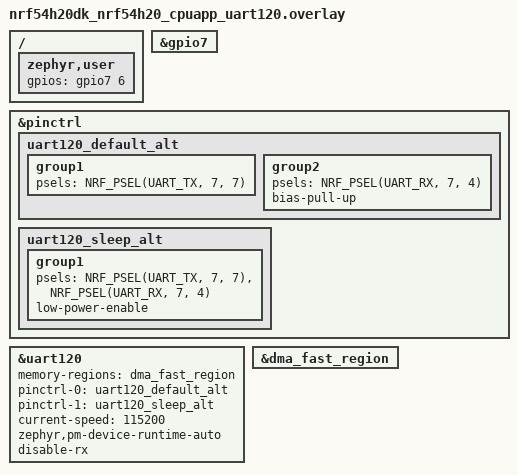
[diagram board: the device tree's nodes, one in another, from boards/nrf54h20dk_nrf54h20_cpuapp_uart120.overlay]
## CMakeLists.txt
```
#
# Copyright (c) 2025 Nordic Semiconductor ASA
#
# SPDX-License-Identifier: LicenseRef-Nordic-5-Clause
#

cmake_minimum_required(VERSION 3.20.0)
find_package(Zephyr REQUIRED HINTS $ENV{ZEPHYR_BASE})
project(uart_baudrate_test)

FILE(GLOB app_sources src/*.c)
target_sources(app PRIVATE ${app_sources})
```

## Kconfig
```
#
# Copyright (c) 2025 Nordic Semiconductor ASA
#
# SPDX-License-Identifier: LicenseRef-Nordic-5-Clause
#

source "Kconfig.zephyr"

config ALLOWED_DEVIATION
	int "Allowed deviation (%) for UART timing checks"
	default 25
	range 0 100
	help
	  Maximum allowed deviation (%) from the programmed values for the test to be
	  considered a PASS. For example, if set to 5, the measured period of bit
	  can deviate by up to 5% from the programmed values for the test to pass.
```

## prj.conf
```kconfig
CONFIG_SERIAL=y
CONFIG_ZTEST=y
CONFIG_UART_USE_RUNTIME_CONFIGURE=y
CONFIG_CBPRINTF_FP_SUPPORT=y
CONFIG_SPEED_OPTIMIZATIONS=y
CONFIG_UART_ASYNC_API=y
```

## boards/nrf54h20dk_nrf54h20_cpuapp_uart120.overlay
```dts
/*
 * Test requires wire connection between:
 *  - uart120 TX at P7.07 <-> GPIO input at P7.06
 */

/ {
	zephyr,user {
		gpios = <&gpio7 6 GPIO_ACTIVE_HIGH>;
	};
};

&gpio7 {
	status = "okay";
};

&pinctrl {
	uart120_default_alt: uart120_default_alt {
		group1 {
			psels = <NRF_PSEL(UART_TX, 7, 7)>;
		};
		group2 {
			psels = <NRF_PSEL(UART_RX, 7, 4)>;
			bias-pull-up;
		};
	};

	uart120_sleep_alt: uart120_sleep_alt {
		group1 {
			psels = <NRF_PSEL(UART_TX, 7, 7)>,
				<NRF_PSEL(UART_RX, 7, 4)>;
			low-power-enable;
		};
	};
};

dut: &uart120 {
	status = "okay";
	memory-regions = <&dma_fast_region>;
	pinctrl-0 = <&uart120_default_alt>;
	pinctrl-1 = <&uart120_sleep_alt>;
	pinctrl-names = "default", "sleep";
	current-speed = <115200>;
	zephyr,pm-device-runtime-auto;
	disable-rx;
};

&dma_fast_region {
	status = "okay";
};
```

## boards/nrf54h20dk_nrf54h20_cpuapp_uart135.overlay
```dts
/*
 * Test requires wire connection between:
 *  - uart135 TX at P0.06 <-> GPIO input at P0.07
 */

/ {
	zephyr,user {
		gpios = <&gpio0 7 GPIO_ACTIVE_HIGH>;
	};
};

&gpio0 {
	status = "okay";
};

&pinctrl {
	uart135_default_alt: uart135_default_alt {
		group1 {
			psels = <NRF_PSEL(UART_RX, 0, 9)>;
				bias-pull-up;
		};
		group2 {
			psels = <NRF_PSEL(UART_TX, 0, 6)>;
		};
	};

	uart135_sleep_alt: uart135_sleep_alt {
		group1 {
			psels = <NRF_PSEL(UART_TX, 0, 6)>,
				<NRF_PSEL(UART_RX, 0, 9)>;
			low-power-enable;
		};
	};
};

dut: &uart135 {
	status = "okay";
	memory-regions = <&cpuapp_dma_region>;
	pinctrl-0 = <&uart135_default_alt>;
	pinctrl-1 = <&uart135_sleep_alt>;
	pinctrl-names = "default", "sleep";
	current-speed = <115200>;
	disable-rx;
};
```

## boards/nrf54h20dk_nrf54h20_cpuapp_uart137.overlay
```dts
/*
 * Test requires wire connection between:
 *  - uart137 TX at P0.08 <-> GPIO input at P0.09
 */

/ {
	zephyr,user {
		gpios = <&gpio0 9 GPIO_ACTIVE_HIGH>;
	};
};

&gpio0 {
	status = "okay";
};

&pinctrl {
	uart137_default_alt: uart137_default_alt {
		group1 {
			psels = <NRF_PSEL(UART_RX, 0, 7)>;
			bias-pull-up;
		};
		group2 {
			psels = <NRF_PSEL(UART_TX, 0, 8)>;
		};
	};

	uart137_sleep_alt: uart137_sleep_alt {
		group1 {
			psels = <NRF_PSEL(UART_TX, 0, 8)>,
				<NRF_PSEL(UART_RX, 0, 9)>;
			low-power-enable;
		};
	};
};

dut: &uart137 {
	status = "okay";
	memory-regions = <&cpuapp_dma_region>;
	pinctrl-0 = <&uart137_default_alt>;
	pinctrl-1 = <&uart137_sleep_alt>;
	pinctrl-names = "default", "sleep";
	current-speed = <115200>;
	disable-rx;
};
```

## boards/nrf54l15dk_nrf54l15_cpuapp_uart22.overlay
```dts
/*
 * Test requires wire connection between:
 *  - uart21 TX at P1.9 <-> GPIO input at P1.8
 */


/ {
	zephyr,user {
		gpios = <&gpio1 8 GPIO_ACTIVE_HIGH>;
	};
};

&gpio1 {
	status = "okay";
};

&pinctrl {
	uart22_default: uart22_default {
		group1 {
			psels = <NRF_PSEL(UART_TX, 1, 9)>,
				<NRF_PSEL(UART_RX, 1, 11)>;
				bias-pull-up;
		};
	};

	uart22_sleep: uart22_sleep {
		group1 {
			psels = <NRF_PSEL(UART_TX, 1, 9)>,
				<NRF_PSEL(UART_RX, 1, 11)>;
			low-power-enable;
		};
	};
};

dut: &uart22 {
	status = "okay";
	current-speed = <115200>;
	pinctrl-0 = <&uart22_default>;
	pinctrl-1 = <&uart22_sleep>;
	pinctrl-names = "default", "sleep";
	disable-rx;
};
```

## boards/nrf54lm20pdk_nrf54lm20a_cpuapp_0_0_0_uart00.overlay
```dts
/*
 * Test requires wire connection between:
 *  - uart00 TX at P2.08 <-> GPIO input at P2.09
 */

/ {
	zephyr,user {
		gpios = <&gpio2 9 GPIO_ACTIVE_HIGH>;
	};
};

&gpio2 {
	status = "okay";
};

&pinctrl {
	uart00_default: uart00_default {
		group1 {
			psels = <NRF_PSEL(UART_TX, 2, 8)>,
				<NRF_PSEL(UART_RX, 2, 7)>;
				bias-pull-up;
		};
	};

	uart00_sleep: uart00_sleep {
		group1 {
			psels = <NRF_PSEL(UART_TX, 2, 8)>,
				<NRF_PSEL(UART_RX, 2, 7)>;
			low-power-enable;
		};
	};
};

dut: &uart00 {
	status = "okay";
	current-speed = <115200>;
	pinctrl-0 = <&uart00_default>;
	pinctrl-1 = <&uart00_sleep>;
	pinctrl-names = "default", "sleep";
	disable-rx;
};
```

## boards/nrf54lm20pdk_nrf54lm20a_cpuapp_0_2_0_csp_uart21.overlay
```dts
/*
 * Test requires wire connection between:
 *  - uart21 TX at P1.13 <-> GPIO input at P1.14
 */

/ {
	zephyr,user {
		gpios = <&gpio1 14 GPIO_ACTIVE_HIGH>;
	};
};

&gpio1 {
	status = "okay";
};

&pinctrl {
	uart21_default: uart21_default {
		group1 {
			psels = <NRF_PSEL(UART_TX, 1, 13)>,
				<NRF_PSEL(UART_RX, 1, 23)>;
				bias-pull-up;
		};
	};

	uart21_sleep: uart21_sleep {
		group1 {
			psels = <NRF_PSEL(UART_TX, 1, 13)>,
				<NRF_PSEL(UART_RX, 1, 23)>;
			low-power-enable;
		};
	};
};

dut: &uart21 {
	status = "okay";
	current-speed = <115200>;
	pinctrl-0 = <&uart21_default>;
	pinctrl-1 = <&uart21_sleep>;
	pinctrl-names = "default", "sleep";
	disable-rx;
};
```

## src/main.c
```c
/*
 * Copyright (c) 2025 Nordic Semiconductor ASA
 *
 * SPDX-License-Identifier: LicenseRef-Nordic-5-Clause
 */

#include <zephyr/device.h>
#include <zephyr/devicetree.h>
#include <zephyr/drivers/uart.h>
#include <zephyr/kernel.h>
#include <zephyr/ztest.h>
#include <zephyr/drivers/gpio.h>
#include <stdlib.h>
#include <math.h>

static const struct gpio_dt_spec gpio_spec =
	GPIO_DT_SPEC_GET_BY_IDX(DT_PATH(zephyr_user), gpios, 0);
static const struct device *const uart_dev = DEVICE_DT_GET(DT_NODELABEL(dut));

static const uint8_t tx_buf[1] = {0x00};

#define PIN_STATE_SIZE 16384
static int pin_state[PIN_STATE_SIZE] = {};

#define REPEAT_NUMBER 10

#ifdef CONFIG_UART_INTERRUPT_DRIVEN
static void uart_fifo_callback(const struct device *dev, void *user_data)
{
	int ret;

	ARG_UNUSED(user_data);

	ret = uart_irq_update(dev);
	zassert_true(ret >= 0, "uart_irq_update: %d\n", ret);

	ret = uart_irq_tx_ready(dev);
	zassert_true(ret >= 0, "uart_irq_tx_ready: %d\n", ret);

	ret = uart_fifo_fill(dev, (uint8_t *)&tx_buf, sizeof(tx_buf));
	zassert_true(ret == sizeof(tx_buf), "uart_fifo_fill: %d\n", ret);
	uart_irq_tx_disable(dev);
}
#endif

static void check_timing(const struct gpio_dt_spec *gpio_dt, uint32_t baudrate)
{
	uint64_t cycles_s_sys;
	struct uart_config test_uart_config;
	int ret;
	uint32_t cycle_start_time;
	uint32_t cycle_stop_time;
	double gpio_read_time_us_mean;
	int32_t start_index;
	int32_t stop_index;
	int32_t start_index_count_zero;
	double bit_diviation_mean;
	double symbol_diviation_mean;

	ret = uart_config_get(uart_dev, &test_uart_config);
	zassert_equal(ret, 0, "uart_config_get: %d\n", ret);

	test_uart_config.parity = UART_CFG_PARITY_EVEN;
	test_uart_config.stop_bits = UART_CFG_STOP_BITS_2;
	test_uart_config.flow_ctrl = UART_CFG_FLOW_CTRL_NONE;
	test_uart_config.baudrate = baudrate;
	ret = uart_configure(uart_dev, &test_uart_config);
	if (ret == -ENOTSUP) {
		TC_PRINT("[%d] Not supported\n", baudrate);
		ztest_test_skip();
	}
	zassert_equal(ret, 0, "uart_configure: %d\n", ret);

	cycles_s_sys = (uint64_t)sys_clock_hw_cycles_per_sec();
	TC_PRINT("Cycles: %llu cycles\n", cycles_s_sys);

	/*
	 * Measure time needed to read gpios
	 */
	gpio_read_time_us_mean = 0;
	for (uint32_t t = 0; t < REPEAT_NUMBER; ++t) {
		cycle_start_time = k_cycle_get_32();
		for (uint32_t i = 0; i < PIN_STATE_SIZE; ++i) {
			pin_state[i] = gpio_pin_get_dt(&gpio_spec);
		}
		cycle_stop_time = k_cycle_get_32();
		double gpio_read_time_us =
			((cycle_stop_time - cycle_start_time) / (double)PIN_STATE_SIZE) *
			(1e6 / cycles_s_sys);
		gpio_read_time_us_mean += gpio_read_time_us;
	}
	gpio_read_time_us_mean /= (double)REPEAT_NUMBER;
	TC_PRINT("GPIO get takes: %.2f us\n", gpio_read_time_us_mean);

	double expected_bit_period_us = 1e6 / (double)baudrate;
	double number_of_bits = 8;

	number_of_bits += 1;
	if (test_uart_config.stop_bits == UART_CFG_STOP_BITS_1) {
		number_of_bits += 1;
	} else if (test_uart_config.stop_bits == UART_CFG_STOP_BITS_2) {
		number_of_bits += 2;
	} else {
		zassert_true(false, "Unsupported stop_bits: %d", test_uart_config.stop_bits);
	}
	if (test_uart_config.parity != UART_CFG_PARITY_NONE) {
		number_of_bits += 1;
	}
	double expected_symbol_period_us = number_of_bits * expected_bit_period_us;

	TC_PRINT("[%d] Expected symbol time: %.2f us, expected bit time: %.2f us\n", baudrate,
		 expected_symbol_period_us, expected_bit_period_us);

	if (expected_bit_period_us < gpio_read_time_us_mean) {
		TC_PRINT("[%d] Not supported - gpio measurement is too slow.\n", baudrate);
		ztest_test_skip();
	}

	start_index_count_zero = 0;
	bit_diviation_mean = 0;
	symbol_diviation_mean = 0;
	for (uint32_t t = 0; t < REPEAT_NUMBER; ++t) {
		/*
		 * Send character
		 */

#ifdef CONFIG_UART_INTERRUPT_DRIVEN
		uart_irq_tx_enable(uart_dev);
#else
		uart_tx(uart_dev, tx_buf, sizeof(tx_buf), 0);
#endif

		/*
		 * Check gpio
		 */
		for (uint32_t i = 0; i < PIN_STATE_SIZE; ++i) {
			pin_state[i] = gpio_pin_get_dt(&gpio_spec);
		}

		/*
		 * Find start of start bit and end of stop bit
		 */
		start_index = -1;
		stop_index = -1;
		for (uint32_t i = 0; i < PIN_STATE_SIZE; ++i) {
			if (-1 == start_index) {
				if (0 == pin_state[i]) {
					start_index = i;
				}
			} else {
				if (-1 == stop_index) {
					if (1 == pin_state[i]) {
						stop_index = i;
					}
				} else {
					zassert_true(1 == pin_state[i], "Unexpected low at %d\n",
						     i);
				}
			}
		}
		TC_PRINT("Start index: %d, stop index: %d\n", start_index, stop_index);
		zassert_true(start_index != -1, "Missing start_index\n");
		zassert_true(stop_index != -1, "Missing stop_index\n");

		double measured_period_us = (stop_index - start_index) * gpio_read_time_us_mean;
		double measured_bit_us = measured_period_us / (double)number_of_bits;

		TC_PRINT("[%d][%s][%d] Measured symbol period: %.2f us, measured bit time: %.2f "
			 "us\n",
			 t, uart_dev->name, baudrate, measured_period_us, measured_bit_us);

		double symbol_diviation = 100 *
					  fabs(measured_period_us - expected_symbol_period_us) /
					  expected_symbol_period_us;
		double bit_diviation = 100 * fabs(measured_bit_us - expected_bit_period_us) /
				       expected_bit_period_us;

		TC_PRINT("[%d][%s][%d] Symbol diviation: %.2f%%, bit diviation: %.2f%%\n", t,
			 uart_dev->name, baudrate, symbol_diviation, bit_diviation);

		if (start_index == 0) {
			start_index_count_zero++;
		}
		symbol_diviation_mean += symbol_diviation;
		bit_diviation_mean += bit_diviation;
	}
	symbol_diviation_mean /= (double)REPEAT_NUMBER;
	bit_diviation_mean /= (double)REPEAT_NUMBER;

	TC_PRINT("[%s][%d] Mean symbol diviation: %.2f%%, mean bit diviation: %.2f%%\n",
		 uart_dev->name, baudrate, symbol_diviation_mean, bit_diviation_mean);

	if (start_index_count_zero == 0) {
		zassert_true(symbol_diviation_mean <= (double)CONFIG_ALLOWED_DEVIATION,
			     "Symbol diviation %0.f%%  higher than %d%%\n", symbol_diviation_mean,
			     CONFIG_ALLOWED_DEVIATION);
		zassert_true(bit_diviation_mean <= (double)CONFIG_ALLOWED_DEVIATION,
			     "Bit diviation %0.f%% higher than %d%%\n", bit_diviation_mean,
			     CONFIG_ALLOWED_DEVIATION);
	} else {
		TC_PRINT("Not checking diviation due to lost start of start bit\n");
	}
}

ZTEST(uart_baudrate_test, test_08_2400)
{
	check_timing(&gpio_spec, 2400);
}

ZTEST(uart_baudrate_test, test_09_4800)
{
	check_timing(&gpio_spec, 4800);
}

ZTEST(uart_baudrate_test, test_10_9600)
{
	check_timing(&gpio_spec, 9600);
}

ZTEST(uart_baudrate_test, test_11_14400)
{
	check_timing(&gpio_spec, 14400);
}
ZTEST(uart_baudrate_test, test_12_19200)
{
	check_timing(&gpio_spec, 19200);
}

ZTEST(uart_baudrate_test, test_13_38400)
{
	check_timing(&gpio_spec, 38400);
}

ZTEST(uart_baudrate_test, test_14_57600)
{
	check_timing(&gpio_spec, 57600);
}

ZTEST(uart_baudrate_test, test_15_115200)
{
	check_timing(&gpio_spec, 115200);
}

ZTEST(uart_baudrate_test, test_16_230400)
{
	check_timing(&gpio_spec, 230400);
}

ZTEST(uart_baudrate_test, test_17_460800)
{
	check_timing(&gpio_spec, 460800);
}

ZTEST(uart_baudrate_test, test_18_576000)
{
	check_timing(&gpio_spec, 576000);
}

ZTEST(uart_baudrate_test, test_19_921600)
{
	check_timing(&gpio_spec, 921600);
}

ZTEST(uart_baudrate_test, test_20_1000000)
{
	check_timing(&gpio_spec, 1000000);
}

ZTEST(uart_baudrate_test, test_21_2000000)
{
	check_timing(&gpio_spec, 2000000);
}

ZTEST(uart_baudrate_test, test_22_3000000)
{
	check_timing(&gpio_spec, 3000000);
}

ZTEST(uart_baudrate_test, test_23_4000000)
{
	check_timing(&gpio_spec, 4000000);
}

ZTEST(uart_baudrate_test, test_24_8000000)
{
	check_timing(&gpio_spec, 8000000);
}

static void *uart_baudrate_test_setup(void)
{
	int ret;

	/*
	 * Wait for any initialization to finish
	 */
	k_msleep(1000);

	zassert_true(gpio_is_ready_dt(&gpio_spec), "GPIO is not ready");
	ret = gpio_pin_configure_dt(&gpio_spec, GPIO_INPUT);
	zassert_true(ret == 0, "gpio_pin_configure_dt: %d", ret);
	zassert_true(device_is_ready(uart_dev), "UART device is not ready");
#ifdef CONFIG_UART_INTERRUPT_DRIVEN
	ret = uart_irq_callback_set(uart_dev, uart_fifo_callback);
	zassert_true(ret == 0, "uart_irq_callback_set: %d", ret);
#endif

	return NULL;
}

ZTEST_SUITE(uart_baudrate_test, NULL, uart_baudrate_test_setup, NULL, NULL, NULL);
```
